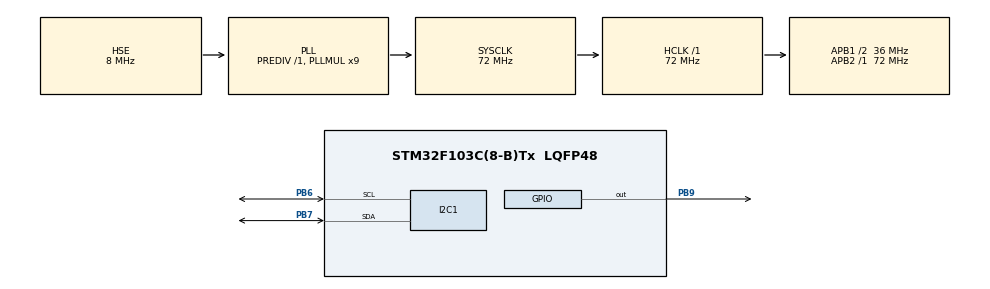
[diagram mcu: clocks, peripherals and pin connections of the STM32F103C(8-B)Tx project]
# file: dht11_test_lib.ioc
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Mcu.Family=STM32F1
Mcu.Name=STM32F103C(8-B)Tx
Mcu.Package=LQFP48
NVIC.PriorityGroup=NVIC_PRIORITYGROUP_4
PA13.Mode=Serial_Wire
PA13.Signal=SYS_JTMS-SWDIO
PA14.Mode=Serial_Wire
PA14.Signal=SYS_JTCK-SWCLK
PB6.Mode=I2C
PB6.Signal=I2C1_SCL
PB7.Mode=I2C
PB7.Signal=I2C1_SDA
PB9.Signal=GPIO_Output
PD0-OSC_IN.Mode=HSE-External-Oscillator
PD0-OSC_IN.Signal=RCC_OSC_IN
PD1-OSC_OUT.Mode=HSE-External-Oscillator
PD1-OSC_OUT.Signal=RCC_OSC_OUT
ProjectManager.HeapSize=0x200
ProjectManager.StackSize=0x400
ProjectManager.TargetToolchain=MDK-ARM V5.32
RCC.AHBFreq_Value=72000000
RCC.APB1CLKDivider=RCC_HCLK_DIV2
RCC.APB1Freq_Value=36000000
RCC.APB1TimFreq_Value=72000000
RCC.APB2Freq_Value=72000000
RCC.APB2TimFreq_Value=72000000
RCC.HCLKFreq_Value=72000000
RCC.PLLMUL=RCC_PLL_MUL9
RCC.PLLSourceVirtual=RCC_PLLSOURCE_HSE
RCC.SYSCLKFreq_VALUE=72000000
RCC.SYSCLKSource=RCC_SYSCLKSOURCE_PLLCLK
RCC.USBFreq_Value=72000000
TIM1.Period=0xffff-1
TIM1.Prescaler=72-1
VP_TIM1_VS_ClockSourceINT.Mode=Internal
board=custom

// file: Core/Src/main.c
/* USER CODE BEGIN Header */
/**
  ******************************************************************************
  * @file           : main.c
  * @brief          : Main program body
  ******************************************************************************
  * @attention
  *
  * Copyright (c) 2023 STMicroelectronics.
  * All rights reserved.
  *
  * This software is licensed under terms that can be found in the LICENSE file
  * in the root directory of this software component.
  * If no LICENSE file comes with this software, it is provided AS-IS.
  *
  ******************************************************************************
  */
/* USER CODE END Header */
#include "main.h"

/* USER CODE BEGIN Includes */
#include "stdio.h"
#include "dht11.h"
#include "liquidcrystal_i2c.h"
/* USER CODE END Includes */

I2C_HandleTypeDef hi2c1;

TIM_HandleTypeDef htim1;

/* USER CODE BEGIN PV */
DHT_Init_t DHT1;

/* USER CODE END PV */

void SystemClock_Config(void);
static void MX_GPIO_Init(void);
static void MX_I2C1_Init(void);
static void MX_TIM1_Init(void);

int main(void)
{
  /* USER CODE BEGIN 1 */
	uint32_t temp,humi;
char str_temp[10];
char str_humi[10];
  /* USER CODE END 1 */

  /* MCU Configuration--------------------------------------------------------*/

  /* Reset of all peripherals, Initializes the Flash interface and the Systick. */
  HAL_Init();

  /* Configure the system clock */
  SystemClock_Config();

  /* Initialize all configured peripherals */
  MX_GPIO_Init();
  MX_I2C1_Init();
  MX_TIM1_Init();
  /* USER CODE BEGIN 2 */
	  LCD_Init(2);
  DHT_Init(&DHT1,DHT11,&htim1,GPIOB,GPIO_PIN_15);
  LCD_PrintStr("Ready ");
  /* USER CODE END 2 */

  /* Infinite loop */
  while (1)
  {
		DHT_ReadTempHum(&DHT1);
	  /*
	  sprintf(str_temp,"%d.%d",DHT1.Temp1,DHT1.Temp2);
	  sprintf(str_humi,"%d.%d",DHT1.RH1,DHT1.RH2);*/
	 sprintf(str_temp,"%d%d.%d",1,DHT1.Temp/100,DHT1.Temp%100);
	  sprintf(str_humi,"%d.%d",DHT1.Humi/100,DHT1.Humi%100);
		  LCD_Clear();
		  LCD_SetCursor(0,0);
		  LCD_PrintStr("Temp : ");
		  LCD_SetCursor(7,0);
		  LCD_PrintStr(str_temp);
		  LCD_SetCursor(0,1);
		  LCD_PrintStr("Humi : ");
		  LCD_SetCursor(7,1);
		  LCD_PrintStr(str_humi);

	  HAL_Delay(1000);
  }
}

void SystemClock_Config(void)
{
  RCC_OscInitTypeDef RCC_OscInitStruct = {0};
  RCC_ClkInitTypeDef RCC_ClkInitStruct = {0};

  /** Initializes the RCC Oscillators according to the specified parameters
  * in the RCC_OscInitTypeDef structure.
  */
  RCC_OscInitStruct.OscillatorType = RCC_OSCILLATORTYPE_HSE;
  RCC_OscInitStruct.HSEState = RCC_HSE_ON;
  RCC_OscInitStruct.HSEPredivValue = RCC_HSE_PREDIV_DIV1;
  RCC_OscInitStruct.HSIState = RCC_HSI_ON;
  RCC_OscInitStruct.PLL.PLLState = RCC_PLL_ON;
  RCC_OscInitStruct.PLL.PLLSource = RCC_PLLSOURCE_HSE;
  RCC_OscInitStruct.PLL.PLLMUL = RCC_PLL_MUL9;
  if (HAL_RCC_OscConfig(&RCC_OscInitStruct) != HAL_OK)
  {
    Error_Handler();
  }

  /** Initializes the CPU, AHB and APB buses clocks
  */
  RCC_ClkInitStruct.ClockType = RCC_CLOCKTYPE_HCLK|RCC_CLOCKTYPE_SYSCLK
                              |RCC_CLOCKTYPE_PCLK1|RCC_CLOCKTYPE_PCLK2;
  RCC_ClkInitStruct.SYSCLKSource = RCC_SYSCLKSOURCE_PLLCLK;
  RCC_ClkInitStruct.AHBCLKDivider = RCC_SYSCLK_DIV1;
  RCC_ClkInitStruct.APB1CLKDivider = RCC_HCLK_DIV2;
  RCC_ClkInitStruct.APB2CLKDivider = RCC_HCLK_DIV1;

  if (HAL_RCC_ClockConfig(&RCC_ClkInitStruct, FLASH_LATENCY_2) != HAL_OK)
  {
    Error_Handler();
  }
}

static void MX_I2C1_Init(void)
{

  hi2c1.Instance = I2C1;
  hi2c1.Init.ClockSpeed = 100000;
  hi2c1.Init.DutyCycle = I2C_DUTYCYCLE_2;
  hi2c1.Init.OwnAddress1 = 0;
  hi2c1.Init.AddressingMode = I2C_ADDRESSINGMODE_7BIT;
  hi2c1.Init.DualAddressMode = I2C_DUALADDRESS_DISABLE;
  hi2c1.Init.OwnAddress2 = 0;
  hi2c1.Init.GeneralCallMode = I2C_GENERALCALL_DISABLE;
  hi2c1.Init.NoStretchMode = I2C_NOSTRETCH_DISABLE;
  if (HAL_I2C_Init(&hi2c1) != HAL_OK)
  {
    Error_Handler();
  }

}

static void MX_TIM1_Init(void)
{

  TIM_ClockConfigTypeDef sClockSourceConfig = {0};
  TIM_MasterConfigTypeDef sMasterConfig = {0};

  htim1.Instance = TIM1;
  htim1.Init.Prescaler = 72-1;
  htim1.Init.CounterMode = TIM_COUNTERMODE_UP;
  htim1.Init.Period = 0xffff-1;
  htim1.Init.ClockDivision = TIM_CLOCKDIVISION_DIV1;
  htim1.Init.RepetitionCounter = 0;
  htim1.Init.AutoReloadPreload = TIM_AUTORELOAD_PRELOAD_DISABLE;
  if (HAL_TIM_Base_Init(&htim1) != HAL_OK)
  {
    Error_Handler();
  }
  sClockSourceConfig.ClockSource = TIM_CLOCKSOURCE_INTERNAL;
  if (HAL_TIM_ConfigClockSource(&htim1, &sClockSourceConfig) != HAL_OK)
  {
    Error_Handler();
  }
  sMasterConfig.MasterOutputTrigger = TIM_TRGO_RESET;
  sMasterConfig.MasterSlaveMode = TIM_MASTERSLAVEMODE_DISABLE;
  if (HAL_TIMEx_MasterConfigSynchronization(&htim1, &sMasterConfig) != HAL_OK)
  {
    Error_Handler();
  }

}

static void MX_GPIO_Init(void)
{
  GPIO_InitTypeDef GPIO_InitStruct = {0};

  /* GPIO Ports Clock Enable */
  __HAL_RCC_GPIOD_CLK_ENABLE();
  __HAL_RCC_GPIOA_CLK_ENABLE();
  __HAL_RCC_GPIOB_CLK_ENABLE();

  /*Configure GPIO pin Output Level */
  HAL_GPIO_WritePin(GPIOB, GPIO_PIN_15, GPIO_PIN_RESET);

  /*Configure GPIO pin : PB9 */
  GPIO_InitStruct.Pin = GPIO_PIN_15;
  GPIO_InitStruct.Mode = GPIO_MODE_INPUT;
  GPIO_InitStruct.Pull = GPIO_PULLUP;
  GPIO_InitStruct.Speed = GPIO_SPEED_FREQ_LOW;
  HAL_GPIO_Init(GPIOB, &GPIO_InitStruct);

}

void Error_Handler(void)
{
  __disable_irq();
  while (1)
  {
  }
}
